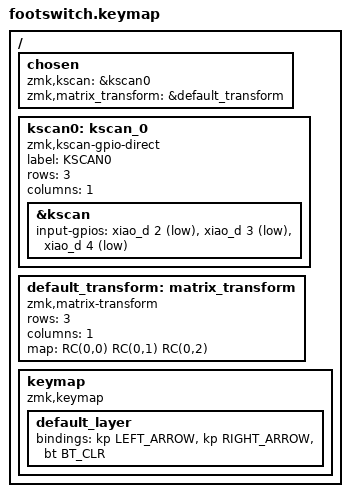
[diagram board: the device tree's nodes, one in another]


#include <behaviors.dtsi>
#include <dt-bindings/zmk/keys.h>
#include <dt-bindings/zmk/bt.h>

/ {

    chosen {
        zmk,kscan = &kscan0;
        zmk,matrix_transform = &default_transform;
    };

    kscan0: kscan_0 {
        compatible = "zmk,kscan-gpio-direct";
        label = "KSCAN0";
        rows = <3>;
        columns = <1>;

        &kscan {
            input-gpios = <
                &xiao_d 2 (GPIO_ACTIVE_LOW | GPIO_PULL_UP) 
                &xiao_d 3 (GPIO_ACTIVE_LOW | GPIO_PULL_UP) 
                &xiao_d 4 (GPIO_ACTIVE_LOW | GPIO_PULL_UP)
            >;
        };
    };

    default_transform: matrix_transform {
        compatible = "zmk,matrix-transform";
        rows = <3>;
        columns = <1>;
        map = <
            RC(0,0)
            RC(0,1)
            RC(0,2)
        >;
    };

    keymap {
        compatible = "zmk,keymap";
        default_layer {
            bindings = <&kp LEFT_ARROW &kp RIGHT_ARROW &bt BT_CLR>;
        };
    };
}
